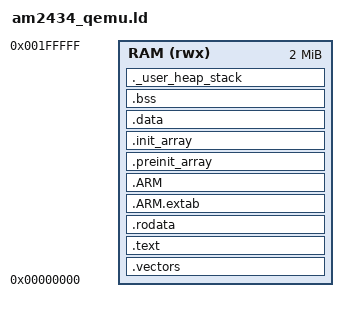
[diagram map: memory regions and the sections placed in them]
/* GCC linker script for AM2434 Nova — QEMU flat layout
 *
 * For QEMU, we place everything contiguously starting at 0x0.
 * The QEMU machine model maps _all_ RAM at 0x0 (ATCM alias).
 * On real hardware, the production linker script splits sections
 * between ATCM/BTCM/MSRAM.
 *
 * Layout: vectors → startup → .text → .rodata → .data → .bss → heap
 */

MEMORY
{
    RAM (rwx) : ORIGIN = 0x00000000, LENGTH = 2048K
}

_estack = ORIGIN(RAM) + LENGTH(RAM);

/* ISR stacks — in the flat QEMU layout these sit at end of RAM */
_isr_stack_top = _estack;

ENTRY(Reset_Handler)

SECTIONS
{
    .vectors :
    {
        . = ALIGN(4);
        KEEP(*(.vectors))
        . = ALIGN(4);
    } > RAM

    .text :
    {
        . = ALIGN(4);
        *(.text)
        *(.text*)
        *(.glue_7)
        *(.glue_7t)
        *(.eh_frame)
        KEEP(*(.init))
        KEEP(*(.fini))
        . = ALIGN(4);
        _etext = .;
    } > RAM

    .rodata :
    {
        . = ALIGN(4);
        *(.rodata)
        *(.rodata*)
        . = ALIGN(4);
    } > RAM

    .ARM.extab :
    {
        *(.ARM.extab* .gnu.linkonce.armextab.*)
    } > RAM

    .ARM :
    {
        __exidx_start = .;
        *(.ARM.exidx*)
        __exidx_end = .;
    } > RAM

    .preinit_array :
    {
        PROVIDE_HIDDEN(__preinit_array_start = .);
        KEEP(*(.preinit_array*))
        PROVIDE_HIDDEN(__preinit_array_end = .);
    } > RAM

    .init_array :
    {
        PROVIDE_HIDDEN(__init_array_start = .);
        KEEP(*(SORT(.init_array.*)))
        KEEP(*(.init_array*))
        PROVIDE_HIDDEN(__init_array_end = .);
    } > RAM

    _sidata = LOADADDR(.data);

    .data :
    {
        . = ALIGN(4);
        _sdata = .;
        *(.data)
        *(.data*)
        . = ALIGN(4);
        _edata = .;
    } > RAM

    .bss :
    {
        . = ALIGN(4);
        _sbss = .;
        __bss_start__ = _sbss;
        *(.bss)
        *(.bss*)
        *(COMMON)
        . = ALIGN(4);
        _ebss = .;
        __bss_end__ = _ebss;
    } > RAM

    ._user_heap_stack (NOLOAD) :
    {
        . = ALIGN(8);
        PROVIDE(end = .);
        PROVIDE(_end = .);
        . = . + 0x10000;   /* 64 KB heap */
        . = ALIGN(8);
    } > RAM

    /DISCARD/ :
    {
        *(.ARM.attributes*)
        *(.comment)
        *(.note*)
    }
}
